AUTOSAR XML (schema 4-2-2)
package /Components
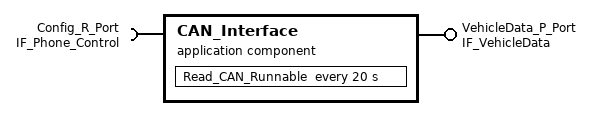
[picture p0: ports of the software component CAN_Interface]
  application sw component type CAN_Interface
    provide port VehicleData_P_Port: provided-interface=IF_VehicleData
    require port Config_R_Port: required-interface=IF_Phone_Control
    behavior CAN_Interface_Behavior
      data received event CAN_Frame_Received: start-on-event=Read_CAN_Runnable
      init event CAN_Init: start-on-event=Read_CAN_Runnable
      timing event CAN_Sample_Timer: start-on-event=Read_CAN_Runnable, period=20
      runnable Read_CAN_Runnable: minimum-start-interval=10, symbol=Runnable_Read_CAN
        data-receive-point-by-values:
          access CAN_Frame_Input: accessed-variable=Config_R_Port.CanRawFrame
        data-send-points:
          access VehicleData_Output: accessed-variable=VehicleData_P_Port.VehicleData
